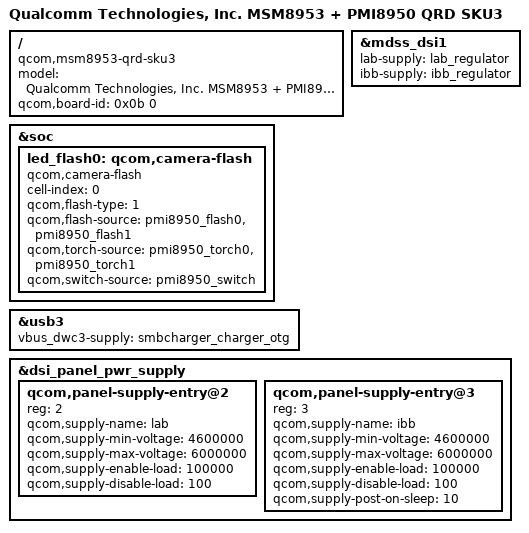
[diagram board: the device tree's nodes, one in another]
/*
 * Copyright (c) 2015-2017, The Linux Foundation. All rights reserved.
 * SPDX-License-Identifier: GPL-2.0-only
 */

#include "msm8953.dtsi"
#include "msm-pmi8950.dtsi"

/ {
	model = "Qualcomm Technologies, Inc. MSM8953 + PMI8950 QRD SKU3";
	compatible = "qcom,msm8953-qrd-sku3",
		   "qcom,msm8953-qrd", "qcom,msm8953", "qcom,qrd";
	qcom,board-id= <0x0b 0>;
};

&soc {
	led_flash0: qcom,camera-flash {
		cell-index = <0>;
		compatible = "qcom,camera-flash";
		qcom,flash-type = <1>;
		qcom,flash-source = <&pmi8950_flash0 &pmi8950_flash1>;
		qcom,torch-source = <&pmi8950_torch0 &pmi8950_torch1>;
		qcom,switch-source = <&pmi8950_switch>;
	};
};

#include "msm8953-qrd-sku3.dtsi"

&usb3 {
	vbus_dwc3-supply = <&smbcharger_charger_otg>;
};

&mdss_dsi1 {
	lab-supply = <&lab_regulator>;
	ibb-supply = <&ibb_regulator>;
};

&dsi_panel_pwr_supply {
	qcom,panel-supply-entry@2 {
		reg = <2>;
		qcom,supply-name = "lab";
		qcom,supply-min-voltage = <4600000>;
		qcom,supply-max-voltage = <6000000>;
		qcom,supply-enable-load = <100000>;
		qcom,supply-disable-load = <100>;
	};

	qcom,panel-supply-entry@3 {
		reg = <3>;
		qcom,supply-name = "ibb";
		qcom,supply-min-voltage = <4600000>;
		qcom,supply-max-voltage = <6000000>;
		qcom,supply-enable-load = <100000>;
		qcom,supply-disable-load = <100>;
		qcom,supply-post-on-sleep = <10>;
	};
};

#include "mido/msm8953-mido.dtsi"
